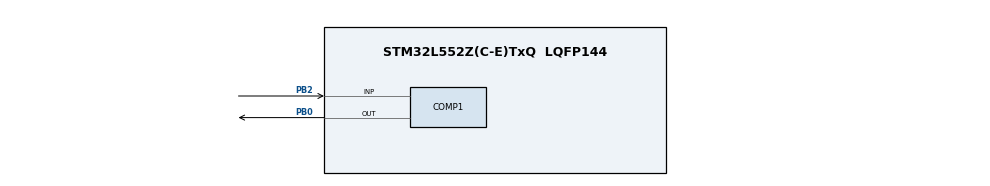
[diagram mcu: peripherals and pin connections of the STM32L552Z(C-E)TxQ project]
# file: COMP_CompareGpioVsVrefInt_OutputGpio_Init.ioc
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COMP1.Hysteresis=COMP_HYSTERESIS_NONE
COMP1.Mode=COMP_POWERMODE_MEDIUMSPEED
Mcu.Family=STM32L5
Mcu.Name=STM32L552Z(C-E)TxQ
Mcu.Package=LQFP144
Mcu.TrustZone=disable
NVIC.PriorityGroup=NVIC_PRIORITYGROUP_3
PB0.Mode=ExternalOutput
PB0.Signal=COMP1_OUT
PB2.Mode=INP
PB2.Signal=COMP1_INP
ProjectManager.HeapSize=0x200
ProjectManager.StackSize=0x400
ProjectManager.TargetToolchain=EWARM V8.32
RCC.AHBFreq_Value=110000000
RCC.APB1Freq_Value=110000000
RCC.APB1TimFreq_Value=110000000
RCC.APB2Freq_Value=110000000
RCC.APB2TimFreq_Value=110000000
RCC.CortexFreq_Value=110000000
RCC.HCLKFreq_Value=110000000
RCC.HSE_VALUE=16000000
RCC.HSI48_VALUE=48000000
RCC.HSI_VALUE=16000000
RCC.LSE_VALUE=32768
RCC.MSI_VALUE=4000000
RCC.PLLN=55
RCC.SYSCLKFreq_VALUE=110000000
RCC.SYSCLKSource=RCC_SYSCLKSOURCE_PLLCLK
RCC.VCOOutputFreq_Value=220000000
VP_COMP1_VS_VREFINT.Mode=VREFINT
VP_ICACHE_VS_ICACHE.Mode=DirectMappedCache
VP_PWR_VS_DBSignals.Mode=DisableDeadBatterySignals
board=custom

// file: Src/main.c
/* USER CODE BEGIN Header */
/**
  ******************************************************************************
  * @file           : main.c
  * @brief          : Main program body
  ******************************************************************************
  * @attention
  *
  * Copyright (c) 2019 STMicroelectronics.
  * All rights reserved.
  *
  * This software is licensed under terms that can be found in the LICENSE file
  * in the root directory of this software component.
  * If no LICENSE file comes with this software, it is provided AS-IS.
  *
  ******************************************************************************
  */
/* USER CODE END Header */
#include "main.h"

void SystemClock_Config(void);
static void MX_GPIO_Init(void);
static void MX_ICACHE_Init(void);
static void MX_COMP1_Init(void);
/* USER CODE BEGIN PFP */
void Activate_COMP(void);
void LED_Init(void);
void LED_On(void);
void LED_Off(void);
/* USER CODE END PFP */

int main(void)
{

  /* MCU Configuration--------------------------------------------------------*/

  /* Reset of all peripherals, Initializes the Flash interface and the Systick. */
  LL_APB2_GRP1_EnableClock(LL_APB2_GRP1_PERIPH_SYSCFG);
  LL_APB1_GRP1_EnableClock(LL_APB1_GRP1_PERIPH_PWR);

  /* System interrupt init*/
  NVIC_SetPriorityGrouping(NVIC_PRIORITYGROUP_3);

  /** Disable the internal Pull-Up in Dead Battery pins of UCPD peripheral
  */
  LL_PWR_DisableUCPDDeadBattery();

  /* Configure the system clock */
  SystemClock_Config();

  /* Initialize all configured peripherals */
  MX_GPIO_Init();
  MX_ICACHE_Init();
  MX_COMP1_Init();
  /* USER CODE BEGIN 2 */
  /* Initialize LED_GREEN */
  LED_Init();

  /* Activate comparator */
  Activate_COMP();

  /* Lock comparator instance */
  //LL_COMP_Lock(COMP1);
  /* USER CODE END 2 */

  /* Infinite loop */
  /* USER CODE BEGIN WHILE */
  while (1)
  {
    /* Set LED state in function of state of GPIO connected to                */
    /* comparator output.                                                     */
    /* Note: State of GPIO is monitored for the purpose of this example.      */
    /*       An alternate solution is to monitor directly comparator output   */
    /*       using function "LL_COMP_ReadOutputLevel()".                      */
    if (LL_GPIO_IsInputPinSet(GPIOB, LL_GPIO_PIN_0) != 0)
    {
      LED_On();
    }
    else
    {
      LED_Off();
    }
    /* USER CODE END WHILE */

  }
}

void SystemClock_Config(void)
{
  LL_FLASH_SetLatency(LL_FLASH_LATENCY_5);
  while(LL_FLASH_GetLatency()!= LL_FLASH_LATENCY_5)
  {
  }

  LL_PWR_SetRegulVoltageScaling(LL_PWR_REGU_VOLTAGE_SCALE0);
  LL_RCC_MSI_Enable();

   /* Wait till MSI is ready */
  while(LL_RCC_MSI_IsReady() != 1)
  {
  }

  LL_RCC_MSI_EnableRangeSelection();
  LL_RCC_MSI_SetRange(LL_RCC_MSIRANGE_6);
  LL_RCC_MSI_SetCalibTrimming(0);
  LL_RCC_PLL_ConfigDomain_SYS(LL_RCC_PLLSOURCE_MSI, LL_RCC_PLLM_DIV_1, 55, LL_RCC_PLLR_DIV_2);
  LL_RCC_PLL_EnableDomain_SYS();
  LL_RCC_PLL_Enable();

   /* Wait till PLL is ready */
  while(LL_RCC_PLL_IsReady() != 1)
  {
  }

   /* Intermediate AHB prescaler 2 when target frequency clock is higher than 80 MHz */
   LL_RCC_SetAHBPrescaler(LL_RCC_SYSCLK_DIV_2);

  LL_RCC_SetSysClkSource(LL_RCC_SYS_CLKSOURCE_PLL);

   /* Wait till System clock is ready */
  while(LL_RCC_GetSysClkSource() != LL_RCC_SYS_CLKSOURCE_STATUS_PLL)
  {
  }

  /* Insure 1us transition state at intermediate medium speed clock*/
  for (__IO uint32_t i = (RCC_MAX_FREQUENCY_MHZ >> 1); i !=0; i--);

  LL_RCC_SetAHBPrescaler(LL_RCC_SYSCLK_DIV_1);
  LL_RCC_SetAPB1Prescaler(LL_RCC_APB1_DIV_1);
  LL_RCC_SetAPB2Prescaler(LL_RCC_APB2_DIV_1);

  LL_Init1msTick(110000000);

  LL_SetSystemCoreClock(110000000);
}

static void MX_COMP1_Init(void)
{

  LL_COMP_InitTypeDef COMP_InitStruct = {0};

  LL_GPIO_InitTypeDef GPIO_InitStruct = {0};

  LL_AHB2_GRP1_EnableClock(LL_AHB2_GRP1_PERIPH_GPIOB);
  /**COMP1 GPIO Configuration
  PB0   ------> COMP1_OUT
  PB2   ------> COMP1_INP
  */
  GPIO_InitStruct.Pin = LL_GPIO_PIN_0;
  GPIO_InitStruct.Mode = LL_GPIO_MODE_ALTERNATE;
  GPIO_InitStruct.Speed = LL_GPIO_SPEED_FREQ_LOW;
  GPIO_InitStruct.OutputType = LL_GPIO_OUTPUT_PUSHPULL;
  GPIO_InitStruct.Pull = LL_GPIO_PULL_NO;
  GPIO_InitStruct.Alternate = LL_GPIO_AF_12;
  LL_GPIO_Init(GPIOB, &GPIO_InitStruct);

  GPIO_InitStruct.Pin = LL_GPIO_PIN_2;
  GPIO_InitStruct.Mode = LL_GPIO_MODE_ANALOG;
  GPIO_InitStruct.Pull = LL_GPIO_PULL_NO;
  LL_GPIO_Init(GPIOB, &GPIO_InitStruct);

  COMP_InitStruct.PowerMode = LL_COMP_POWERMODE_MEDIUMSPEED;
  COMP_InitStruct.InputPlus = LL_COMP_INPUT_PLUS_IO2;
  COMP_InitStruct.InputMinus = LL_COMP_INPUT_MINUS_VREFINT;
  COMP_InitStruct.InputHysteresis = LL_COMP_HYSTERESIS_NONE;
  COMP_InitStruct.OutputPolarity = LL_COMP_OUTPUTPOL_NONINVERTED;
  COMP_InitStruct.OutputBlankingSource = LL_COMP_BLANKINGSRC_NONE;
  LL_COMP_Init(COMP1, &COMP_InitStruct);
  LL_COMP_SetCommonWindowMode(__LL_COMP_COMMON_INSTANCE(COMP1), LL_COMP_WINDOWMODE_DISABLE);

  /* Wait loop initialization and execution */
  /* Note: Variable divided by 2 to compensate partially CPU processing cycles */
  __IO uint32_t wait_loop_index = 0;
  wait_loop_index = (LL_COMP_DELAY_VOLTAGE_SCALER_STAB_US * (SystemCoreClock / (1000000 * 2)));
  while(wait_loop_index != 0)
  {
    wait_loop_index--;
  }
  LL_EXTI_DisableEvent_0_31(LL_EXTI_LINE_21);
  LL_EXTI_DisableIT_0_31(LL_EXTI_LINE_21);

}

static void MX_ICACHE_Init(void)
{

  /** Enable instruction cache in 1-way (direct mapped cache)
  */
  LL_ICACHE_SetMode(LL_ICACHE_1WAY);
  LL_ICACHE_Enable();

}

static void MX_GPIO_Init(void)
{

  /* GPIO Ports Clock Enable */
  LL_AHB2_GRP1_EnableClock(LL_AHB2_GRP1_PERIPH_GPIOB);

}

/* USER CODE BEGIN 4 */
/**
  * @brief  Perform comparator activation procedure
  *         (COMP instance: COMP1).
  * @note   Operations:
  *         - Enable comparator instance
  *         - Wait for comparator startup time
  *           (required to reach propagation delay specification)
  * @param  None
  * @retval None
  */
void Activate_COMP(void)
{
  __IO uint32_t wait_loop_index = 0;

  /* Enable comparator */
  LL_COMP_Enable(COMP1);

  /* Delay for comparator startup time.                                       */
  /* Compute number of CPU cycles to wait for, from delay in us.              */
  /* Note: Variable divided by 2 to compensate partially                      */
  /*       CPU processing cycles (depends on compilation optimization).       */
  /* Note: If system core clock frequency is below 200kHz, wait time          */
  /*       is only a few CPU processing cycles.                               */
  wait_loop_index = ((LL_COMP_DELAY_STARTUP_US * (SystemCoreClock / (100000 * 2))) / 10);
  while(wait_loop_index != 0)
  {
    wait_loop_index--;
  }

}

/**
  * @brief  Initialize LED_GREEN.
  * @param  None
  * @retval None
  */
void LED_Init(void)
{
  /* Enable the LED_GREEN Clock */
  LL_AHB2_GRP1_EnableClock(LL_AHB2_GRP1_PERIPH_GPIOC);

  /* Configure IO in output push-pull mode to drive external LED_GREEN */
  LL_GPIO_SetPinMode(GPIOC, LL_GPIO_PIN_7, LL_GPIO_MODE_OUTPUT);
  /* Reset value is LL_GPIO_OUTPUT_PUSHPULL */
  //LL_GPIO_SetPinOutputTypeGPIOC, LL_GPIO_PIN_7, LL_GPIO_OUTPUT_PUSHPULL);
  /* Reset value is LL_GPIO_SPEED_FREQ_LOW */
  //LL_GPIO_SetPinSpeedGPIOC, LL_GPIO_PIN_7, LL_GPIO_SPEED_FREQ_LOW);
  /* Reset value is LL_GPIO_PULL_NO */
  //LL_GPIO_SetPinPullGPIOC, LL_GPIO_PIN_7, LL_GPIO_PULL_NO);
}

/**
  * @brief  Turn-on LED_GREEN.
  * @param  None
  * @retval None
  */
void LED_On(void)
{
  /* Turn LED_GREEN on */
  LL_GPIO_SetOutputPin(GPIOC, LL_GPIO_PIN_7);
}

/**
  * @brief  Turn-off LED_GREEN.
  * @param  None
  * @retval None
  */
void LED_Off(void)
{
  /* Turn LED_GREEN off */
  LL_GPIO_ResetOutputPin(GPIOC, LL_GPIO_PIN_7);
}
/* USER CODE END 4 */

void Error_Handler(void)
{
  while(1)
  {
  }
}

#ifdef  USE_FULL_ASSERT
/**
  * @brief  Reports the name of the source file and the source line number
  *         where the assert_param error has occurred.
  * @param  file: pointer to the source file name
  * @param  line: assert_param error line source number
  * @retval None
  */
void assert_failed(uint8_t *file, uint32_t line)
{
  /* USER CODE BEGIN 6 */
  /* User can add his own implementation to report the file name and line number,
     ex: printf("Wrong parameters value: file %s on line %d\r\n", file, line) */
  /* Infinite loop */
  while (1)
  {}
  /* USER CODE END 6 */
}
#endif /* USE_FULL_ASSERT */
